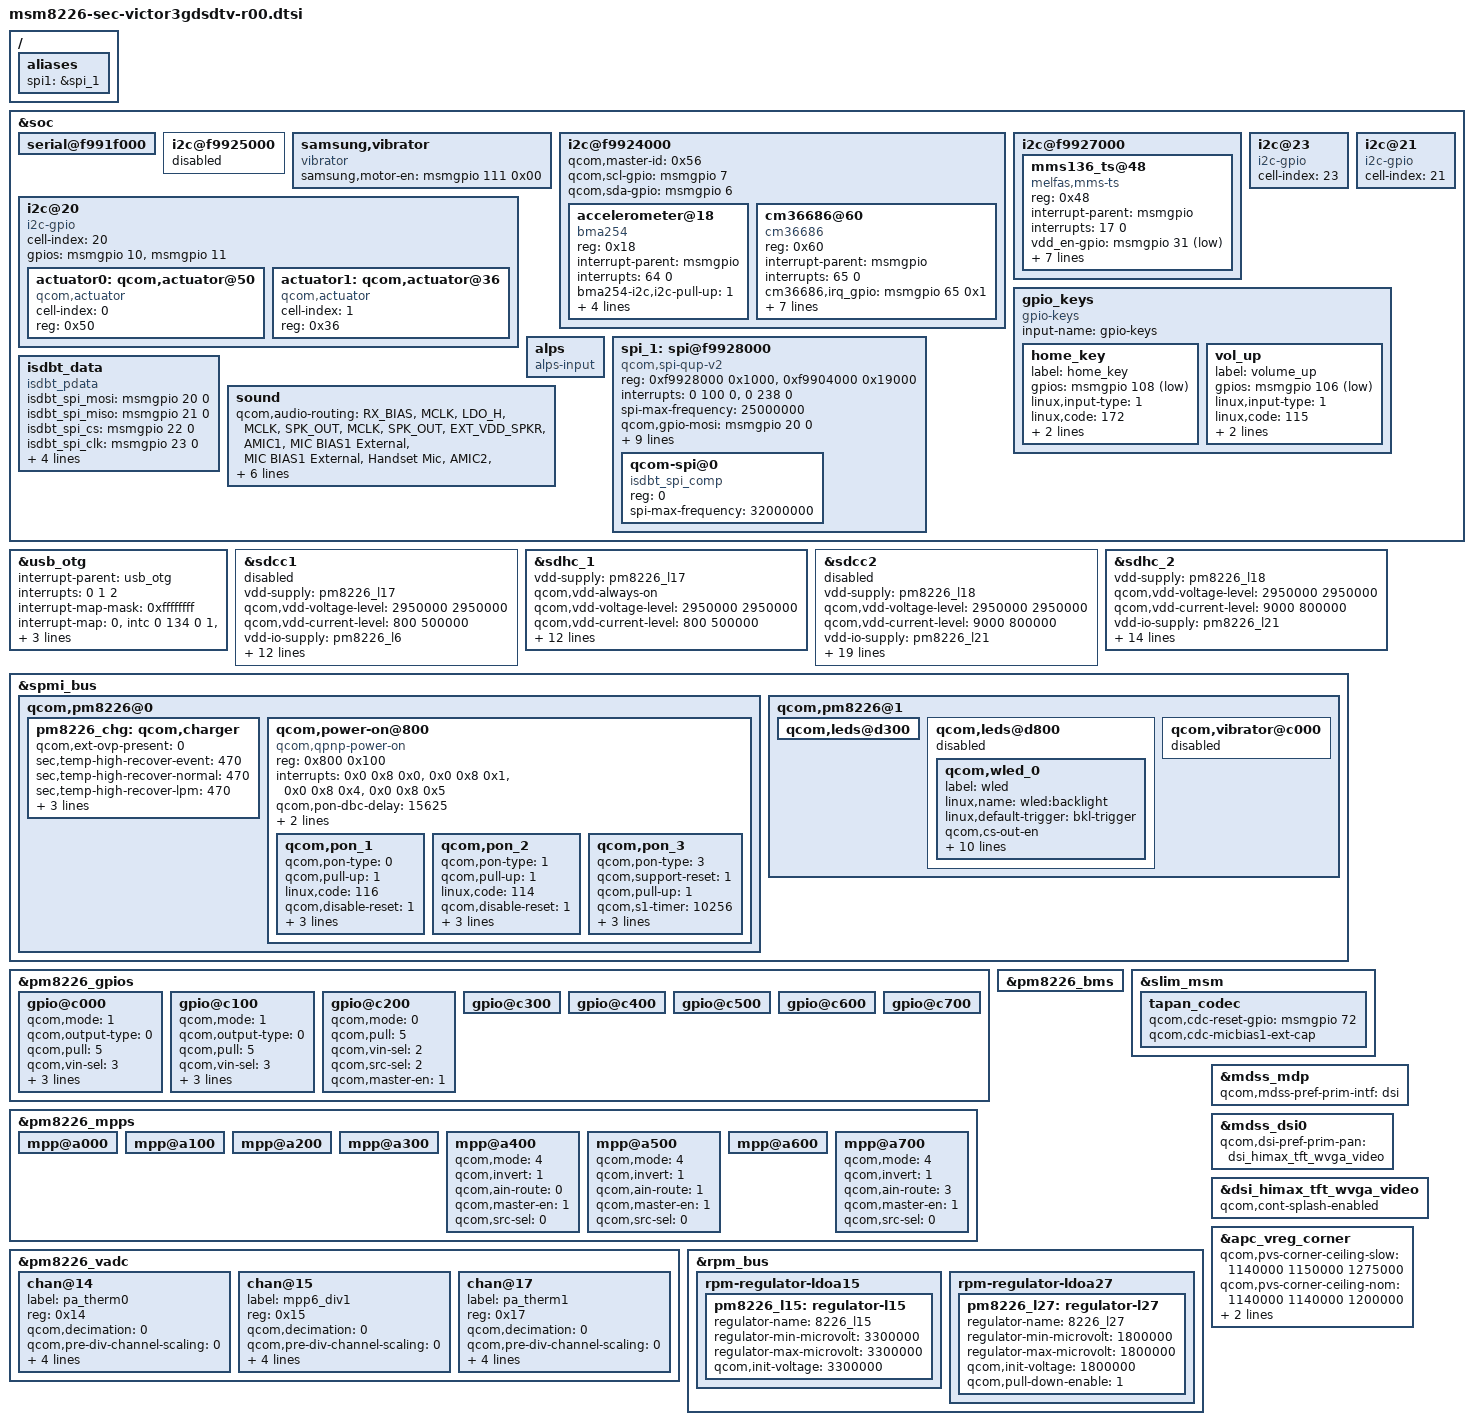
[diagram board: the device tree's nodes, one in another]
/* Copyright (c) 2013, The Linux Foundation. All rights reserved.
 *
 * This program is free software; you can redistribute it and/or modify
 * it under the terms of the GNU General Public License version 2 and
 * only version 2 as published by the Free Software Foundation.
 *
 * This program is distributed in the hope that it will be useful,
 * but WITHOUT ANY WARRANTY; without even the implied warranty of
 * MERCHANTABILITY or FITNESS FOR A PARTICULAR PURPOSE.  See the
 * GNU General Public License for more details.
 */

/include/ "dsi_panel_himax_hx8369b_tft_wvga_video_victor3g.dtsi"
/include/ "msm8226-camera-sensor-mtp-victor3g_ltn.dtsi"
/include/ "msm8226-sm5502.dtsi"
/*/include/ "msm8226-s3ve-sensor-r01.dtsi"*/

/ {
	aliases {
		spi1 = &spi_1;
	};
};

&soc {
	serial@f991f000 { /* BLSP 1 UART 2 */
		status = "ok";
	};

	i2c@f9925000 { /* BLSP1 QUP2*/
		status = "disable";
	};

	samsung,vibrator{
		compatible = "vibrator";
		samsung,motor-en = <&msmgpio 111 0x00>;
		status = "ok";
    };

	i2c@f9924000 { /* BLSP1 QUP1 */
		qcom,master-id = <0x56>;
		qcom,scl-gpio = <&msmgpio 7 0>;
		qcom,sda-gpio = <&msmgpio 6 0>;
		accelerometer@18 {
			compatible = "bma254";
			reg = <0x18>;
			interrupt-parent = <&msmgpio>;
			interrupts = <64 0>;
			bma254-i2c,i2c-pull-up = <1>;
			bma254-i2c,reg_vdd = "8226_l19";
			bma254,irq-gpio = <&msmgpio 64 0x1>;
			bma254-i2c,used_chip = "BMA25X_ENABLED";
			bma254,position = <1>;
		};
		cm36686@60 {
			compatible = "cm36686";
			reg = <0x60>;
			interrupt-parent = <&msmgpio>;
			interrupts = <65 0>;
			cm36686,irq_gpio = <&msmgpio 65 0x1>;
			cm36686,leden_gpio = <&msmgpio 63 0x1>;
			cm36686,default_hi_thd = <34>;
			cm36686,default_low_thd = <30>;
			cm36686,cancel_hi_thd = <34>;
			cm36686,cancel_low_thd = <30>;
			reg_vdd-supply = <&pm8226_l19>;
			reg_vio-supply = <&pm8226_lvs1>;
			status = "okay";
		};
	};

	i2c@f9927000 { /* BLSP1 QUP4 */

		mms136_ts@48 {
			compatible = "melfas,mms-ts";
			reg = <0x48>;
			interrupt-parent = <&msmgpio>;
			interrupts = <17 0>;
			vdd_en-gpio = <&msmgpio 31 0x01>;
			vcc_i2c-supply = <&pm8226_lvs1>;
			melfas,scl-gpio = <&msmgpio 19 0x00>;
			melfas,sda-gpio = <&msmgpio 18 0x00>;
			melfas,irq-gpio = <&msmgpio 17 0x00>;
			melfas,panel-coords = <0  0 480 800>;
			melfas,config_fw_version = "melfas mms136";
			melfas,i2c-pull-up = <1>;
		};
	};

	i2c@23 {
		cell-index = <23>;
		compatible = "i2c-gpio";
	};

	i2c@21 { 
		cell-index = <21>;
		compatible = "i2c-gpio";
	};

	i2c@20 {
		cell-index = <20>;
		compatible = "i2c-gpio";
		gpios = <&msmgpio 10 0 /* sda */
			&msmgpio 11 0 /* scl */>;

		actuator0: qcom,actuator@50 {
			compatible = "qcom,actuator";
			cell-index = <0>;
			reg = <0x50>;
		};
		actuator1: qcom,actuator@36 {
			compatible = "qcom,actuator";
			cell-index = <1>;
			reg = <0x36>;
		};
	};    

	gpio_keys {
		compatible = "gpio-keys";
		input-name = "gpio-keys";

		home_key {
			label = "home_key";
			gpios = <&msmgpio 108 0x1>;
			linux,input-type = <1>;
			linux,code = <172>;
			gpio-key,wakeup;
			debounce-interval = <15>;
		};
/*
		vol_down {
			label = "volume_down";
			gpios = <&msmgpio 107 0x1>;
			linux,input-type = <1>;
			linux,code = <114>;
			gpio-key,wakeup;
			debounce-interval = <15>;
		};
*/
		vol_up {
			label = "volume_up";
			gpios = <&msmgpio 106 0x1>;
			linux,input-type = <1>;
			linux,code = <115>;
			gpio-key,wakeup;
			debounce-interval = <15>;
		};
	};
	alps {
			compatible = "alps-input";
	};

	spi_1: spi@f9928000 { /* BLSP1 QUP6 */
		compatible = "qcom,spi-qup-v2";
		#address-cells = <1>;
		#size-cells = <0>;
		reg-names = "spi_physical", "spi_bam_physical";
		reg = <0xf9928000 0x1000>, <0xf9904000 0x19000>;
		interrupt-names = "spi_irq", "spi_bam_irq";
		interrupts = <0 100 0>, <0 238 0>;
		spi-max-frequency = <25000000>;

		qcom,gpio-mosi = <&msmgpio 20 0>;
		qcom,gpio-miso = <&msmgpio 21 0>;
		qcom,gpio-cs0 = <&msmgpio 22 0>;
		qcom,gpio-clk = <&msmgpio 23 0>;
		
		qcom,infinite-mode = <0>;
		qcom,use-bam;
		qcom,ver-reg-exists;
		qcom,bam-consumer-pipe-index = <22>;
		qcom,bam-producer-pipe-index = <23>;
		qcom,master-id = <86>;

		qcom-spi@0 {
			compatible = "isdbt_spi_comp";
			reg = <0>;
			spi-max-frequency = <32000000>;
		};
	};

	isdbt_data {
		compatible = "isdbt_pdata";
		isdbt_spi_mosi = <&msmgpio 20 0>;
		isdbt_spi_miso = <&msmgpio 21 0>;
		isdbt_spi_cs = <&msmgpio 22 0>;
		isdbt_spi_clk = <&msmgpio 23 0>;
		isdbt_pwr_en = <&msmgpio 36 0>;
		isdbt_pwr_en2 = <&msmgpio 110 0>;
		isdbt_irq = <&msmgpio 49 0>;
		isdbt_rst = <&msmgpio 67 0>;
	};

	sound {
		qcom,audio-routing =
			"RX_BIAS", "MCLK",
			"LDO_H", "MCLK",
			"SPK_OUT", "MCLK",
			"SPK_OUT", "EXT_VDD_SPKR",
			"AMIC1", "MIC BIAS1 External",
			"MIC BIAS1 External", "Handset Mic",
			"AMIC2", "MIC BIAS2 External",
			"MIC BIAS2 External", "Headset Mic",
			"AMIC3", "MIC BIAS1 External",
			"MIC BIAS1 External", "ANCRight Headset Mic",
			"AMIC4", "MIC BIAS2 External",
			"MIC BIAS2 External", "ANCLeft Headset Mic";

		qcom,cdc-mclk-gpios = <&pm8226_gpios 1 0>;
		/*qcom,cdc-vdd-spkr-gpios = <&pm8226_gpios 2 0>;*/
	};
};

&usb_otg {
	#address-cells = <0>;
	interrupt-parent = <&usb_otg>;
	interrupts = <0 1 2>;
	#interrupt-cells = <1>;
	interrupt-map-mask = <0xffffffff>;
	interrupt-map = <0 &intc 0 134 0
			1 &intc 0 140 0
			2 &spmi_bus 0x0 0x0 0x9 0x0>;
	interrupt-names = "core_irq", "async_irq", "pmic_id_irq";

	qcom,hsusb-otg-mode = <3>;
	vbus_otg-supply = <&pm8226_chg_otg>;
};

&sdcc1 {
	vdd-supply = <&pm8226_l17>;
	qcom,vdd-voltage-level = <2950000 2950000>;
	qcom,vdd-current-level = <800 500000>;

	vdd-io-supply = <&pm8226_l6>;
	qcom,vdd-io-always-on;
	qcom,vdd-io-voltage-level = <1800000 1800000>;
	qcom,vdd-io-current-level = <250 154000>;

	qcom,pad-pull-on = <0x0 0x3 0x3>; /* no-pull, pull-up, pull-up */
	qcom,pad-pull-off = <0x0 0x3 0x3>; /* no-pull, pull-up, pull-up */
	qcom,pad-drv-on = <0x4 0x4 0x4>; /* 10mA, 10mA, 10mA */
	qcom,pad-drv-off = <0x0 0x0 0x0>; /* 2mA, 2mA, 2mA */

	qcom,clk-rates = <400000 25000000 50000000 100000000 200000000>;
	qcom,sup-voltages = <2950 2950>;

	qcom,bus-speed-mode = "HS200_1p8v", "DDR_1p8v";
	qcom,nonremovable;

	status = "disabled";
};

&sdhc_1 {
	vdd-supply = <&pm8226_l17>;
	qcom,vdd-always-on;
	qcom,vdd-voltage-level = <2950000 2950000>;
	qcom,vdd-current-level = <800 500000>;

	vdd-io-supply = <&pm8226_l6>;
	qcom,vdd-io-always-on;
	qcom,vdd-io-voltage-level = <1800000 1800000>;
	qcom,vdd-io-current-level = <250 154000>;

	qcom,pad-pull-on = <0x0 0x3 0x3>; /* no-pull, pull-up, pull-up */
	qcom,pad-pull-off = <0x0 0x3 0x3>; /* no-pull, pull-up, pull-up */
	qcom,pad-drv-on = <0x4 0x4 0x4>; /* 10mA, 10mA, 10mA */
	qcom,pad-drv-off = <0x0 0x0 0x0>; /* 2mA, 2mA, 2mA */

	qcom,clk-rates = <400000 25000000 50000000 100000000 200000000>;
	qcom,bus-speed-mode = "HS200_1p8v", "DDR_1p8v";
	qcom,nonremovable;

	status = "ok";
};

&sdcc2 {
	vdd-supply = <&pm8226_l18>;
	qcom,vdd-voltage-level = <2950000 2950000>;
	qcom,vdd-current-level = <9000 800000>;

	vdd-io-supply = <&pm8226_l21>;
	qcom,vdd-io-voltage-level = <1800000 2950000>;
	qcom,vdd-io-current-level = <6 22000>;

	qcom,pad-pull-on = <0x0 0x3 0x3>; /* no-pull, pull-up, pull-up */
	qcom,pad-pull-off = <0x0 0x3 0x3>; /* no-pull, pull-up, pull-up */
	qcom,pad-drv-on = <0x4 0x4 0x4>; /* 10mA, 10mA, 10mA */
	qcom,pad-drv-off = <0x0 0x0 0x0>; /* 2mA, 2mA, 2mA */

	qcom,clk-rates = <400000 25000000 50000000 100000000 200000000>;
	qcom,sup-voltages = <2950 2950>;

	qcom,xpc;
	qcom,bus-speed-mode = "SDR12", "SDR25", "SDR50", "DDR50", "SDR104";
	qcom,current-limit = <600>; #address-cells = <0>; interrupt-parent = <&sdcc2>;
	interrupts = <0 1 2>;
	#interrupt-cells = <1>;
	interrupt-map-mask = <0xffffffff>;
	interrupt-map = <0 &intc 0 125 0
			1 &intc 0 220 0
			2 &msmgpio 38 0x3>;
	interrupt-names = "core_irq", "bam_irq", "status_irq";
	cd-gpios = <&msmgpio 38 0x1>;

	status = "disabled";
};

&sdhc_2 {
	vdd-supply = <&pm8226_l18>;
	qcom,vdd-voltage-level = <2950000 2950000>;
	qcom,vdd-current-level = <9000 800000>;

	vdd-io-supply = <&pm8226_l21>;
	qcom,vdd-io-voltage-level = <1800000 2950000>;
	qcom,vdd-io-current-level = <6 22000>;

	qcom,pad-pull-on = <0x0 0x3 0x3>; /* no-pull, pull-up, pull-up */
	qcom,pad-pull-off = <0x0 0x1 0x1>; /* no-pull, pull-down, pull-down */
	qcom,pad-drv-on = <0x4 0x4 0x4>; /* 10mA, 10mA, 10mA */
	qcom,pad-drv-off = <0x0 0x0 0x0>; /* 2mA, 2mA, 2mA */

	qcom,clk-rates = <400000 25000000 50000000 100000000 200000000>;

	#address-cells = <0>;
	interrupt-parent = <&sdhc_2>;
	interrupts = <0 1 2>;
	#interrupt-cells = <1>;
	interrupt-map-mask = <0xffffffff>;
	interrupt-map = <0 &intc 0 125 0
			1 &intc 0 221 0
			2 &msmgpio 38 0x3>;
	interrupt-names = "hc_irq", "pwr_irq", "status_irq";
	cd-gpios = <&msmgpio 38 0x1>;

	status = "ok";
};

&spmi_bus {
	qcom,pm8226@0 {
		pm8226_chg: qcom,charger {
			qcom,ext-ovp-present = <0>;
			sec,temp-high-recover-event = <470>;
			sec,temp-high-recover-normal = <470>;
			sec,temp-high-recover-lpm = <470>;
		};
		qcom,power-on@800 {
			compatible = "qcom,qpnp-power-on";
			reg = <0x800 0x100>;
			interrupts = <0x0 0x8 0x0>,
				     <0x0 0x8 0x1>,
				     <0x0 0x8 0x4>,
				     <0x0 0x8 0x5>;
			interrupt-names = "kpdpwr", "resin",
					"resin-bark", "kpdpwr-resin-bark";
			qcom,pon-dbc-delay = <15625>;
			qcom,system-reset;
			qcom,s3-debounce = <128>;

			qcom,pon_1 {
				qcom,pon-type = <0>;
				qcom,pull-up = <1>;
				linux,code = <116>;
				qcom,disable-reset = <1>;
				qcom,s1-timer = <6720>;
				qcom,s2-timer = <1000>;
				qcom,s2-type = <7>;
			};

			qcom,pon_2 {
				qcom,pon-type = <1>;
				qcom,pull-up = <1>;
				linux,code = <114>;
				qcom,disable-reset = <1>;
				qcom,s1-timer = <6720>;
				qcom,s2-timer = <2000>;
				qcom,s2-type = <7>;
			};

			qcom,pon_3 {
				qcom,pon-type = <3>;
				qcom,support-reset = <1>;
				qcom,pull-up = <1>;
				qcom,s1-timer = <10256>;
				qcom,s2-timer = <1000>;
				qcom,s2-type = <7>;
				qcom,use-bark;
			};		
		};
	};

	qcom,pm8226@1 {
                qcom,leds@d300 {
                        status = "okay";
                };

		qcom,leds@d800 {
			status = "disabled"; /*If WLED is not used for Backlight control*/
			qcom,wled_0 {		/*for TFT Panel, this to be disabled */
				label = "wled";
				linux,name = "wled:backlight";
				linux,default-trigger = "bkl-trigger";
				qcom,cs-out-en;
				qcom,op-fdbck = <1>;
				qcom,default-state = "off";
				qcom,max-current = <20>;
				qcom,ctrl-delay-us = <0>;
				qcom,boost-curr-lim = <3>;
				qcom,cp-sel = <0>;
				qcom,switch-freq = <11>;
				qcom,ovp-val = <0>;
				qcom,num-strings = <1>;
				qcom,id = <0>;
			};
		};
		qcom,vibrator@c000 {
				status = "disabled";
		};
	};
};

&pm8226_gpios {
	gpio@c000 { /* GPIO 1 */
		/* XO_PMIC_CDC_MCLK enable for tapan codec */
		qcom,mode = <1>;		/* Digital output */
		qcom,output-type = <0>;	/* CMOS logic */
		qcom,pull = <5>;		/* QPNP_PIN_PULL_NO*/
		qcom,vin-sel = <3>;		/* QPNP_PIN_VIN3 */
		qcom,out-strength = <3>;/* QPNP_PIN_OUT_STRENGTH_HIGH */
		qcom,src-sel = <2>;		/* QPNP_PIN_SEL_FUNC_1 */
		qcom,master-en = <1>;	/* Enable GPIO */
	};

	gpio@c100 { /* GPIO 2 */
		qcom,mode = <1>;
		qcom,output-type = <0>;
		qcom,pull = <5>;
		qcom,vin-sel = <3>;
		qcom,out-strength = <3>;
		qcom,src-sel = <2>;
		qcom,master-en = <1>;
	};

	gpio@c200 { /* GPIO 3 */
		qcom,mode = <0>;		/* QPNP_PIN_MODE_DIG_IN */
		qcom,pull = <5>;		/* QPNP_PIN_PULL_NO */
		qcom,vin-sel = <2>;		/* QPNP_PIN_VIN2 */
		qcom,src-sel = <2>;		/* QPNP_PIN_SEL_FUNC_1 */
		qcom,master-en = <1>;
	};

	gpio@c300 { /* GPIO 4 */
	};

	gpio@c400 { /* GPIO 5 */
	};

	gpio@c500 { /* GPIO 6 */
	};

	gpio@c600 { /* GPIO 7 */
	};

	gpio@c700 { /* GPIO 8 */
	};
};

&pm8226_mpps {
	mpp@a000 { /* MPP 1 */
	};

	mpp@a100 { /* MPP 2 */
	};

	mpp@a200 { /* MPP 3 */
	};

	mpp@a300 { /* MPP 4 */
	};

	mpp@a400 { /* MPP 5 */
		/* PA_THERM0 config */
		qcom,mode = <4>; /* AIN input */
		qcom,invert = <1>; /* Enable MPP */
		qcom,ain-route = <0>; /* AMUX 5 */
		qcom,master-en = <1>;
		qcom,src-sel = <0>; /* Function constant */
	};

	mpp@a500 { /* MPP 6 */
		qcom,mode = <4>; /* AIN input */
		qcom,invert = <1>; /* Enable MPP */
		qcom,ain-route = <1>; /* AMUX 6 */
		qcom,master-en = <1>;
		qcom,src-sel = <0>; /* Function constant */
	};

	mpp@a600 { /* MPP 7 */
	};

	mpp@a700 { /* MPP 8 */
		/* PA_THERM1 config */
		qcom,mode = <4>; /* AIN input */
		qcom,invert = <1>; /* Enable MPP */
		qcom,ain-route = <3>; /* AMUX 8 */
		qcom,master-en = <1>;
		qcom,src-sel = <0>; /* Function constant */
	};
};

&pm8226_vadc {
	chan@14 {
		label = "pa_therm0";
		reg = <0x14>;
		qcom,decimation = <0>;
		qcom,pre-div-channel-scaling = <0>;
		qcom,calibration-type = "ratiometric";
		qcom,scale-function = <2>;
		qcom,hw-settle-time = <2>;
		qcom,fast-avg-setup = <0>;
	};
	chan@15 {
		label = "mpp6_div1";
		reg = <0x15>;
		qcom,decimation = <0>;
		qcom,pre-div-channel-scaling = <0>;
		qcom,calibration-type = "absolute";
		qcom,scale-function = <0>;
		qcom,hw-settle-time = <0>;
		qcom,fast-avg-setup = <0>;
	};

	chan@17 {
		label = "pa_therm1";
		reg = <0x17>;
		qcom,decimation = <0>;
		qcom,pre-div-channel-scaling = <0>;
		qcom,calibration-type = "ratiometric";
		qcom,scale-function = <2>;
		qcom,hw-settle-time = <2>;
		qcom,fast-avg-setup = <0>;
	};
};

&pm8226_bms {
	status = "ok";
};

&pm8226_chg {
	qcom,charging-disabled;
	sec,imax-ta = <1000>;
	sec,imax-usb = <500>;
};

&slim_msm {
	tapan_codec {
		qcom,cdc-reset-gpio = <&msmgpio 72 0>;
		qcom,cdc-micbias1-ext-cap;
	};
};

&rpm_bus {
	rpm-regulator-ldoa15 {
		status = "okay";
		pm8226_l15: regulator-l15 {
			regulator-name = "8226_l15";
			regulator-min-microvolt = <3300000>;
			regulator-max-microvolt = <3300000>;
			qcom,init-voltage = <3300000>;
			status = "okay";
		};
	};

	rpm-regulator-ldoa27 {
		status = "okay";
		pm8226_l27: regulator-l27 {
			regulator-name = "8226_l27";
			regulator-min-microvolt = <1800000>;
			regulator-max-microvolt = <1800000>;
			qcom,init-voltage = <1800000>;
			qcom,pull-down-enable = <1>;
			status = "okay";
		};
	};
};

&mdss_mdp {
	qcom,mdss-pref-prim-intf = "dsi";
};

&mdss_dsi0 {
	qcom,dsi-pref-prim-pan = <&dsi_himax_tft_wvga_video>;
};

&dsi_himax_tft_wvga_video {
	qcom,cont-splash-enabled;
};

&apc_vreg_corner {
	qcom,pvs-corner-ceiling-slow = <1140000 1150000 1275000>;
	qcom,pvs-corner-ceiling-nom  = <1140000 1140000 1200000>;
	qcom,pvs-corner-ceiling-fast = <1140000 1140000 1140000>;
};

